# LPC5411x register map
Vendor: nxp.com; File version: 1.2
CPU: CM4 r0p1, little endian, MPU, FPU, VTOR, vendor SysTick, 3 interrupt priority bits
Registers are 32-bit, read-write, reset 0x0 unless marked. A register's access mark holds for its fields unless they carry their own. Offsets are from the block's base; [hi:lo] are bit positions; lines under a group give offsets from that group; {n}, {i} and the like mark numbered series.

## MRT — LPC5411x Multi-Rate Timer (MRT)
Base 0x4000D000
{0x0+0x10*i} MyAddressBlock1_RF[{i}] (i=0..3) group
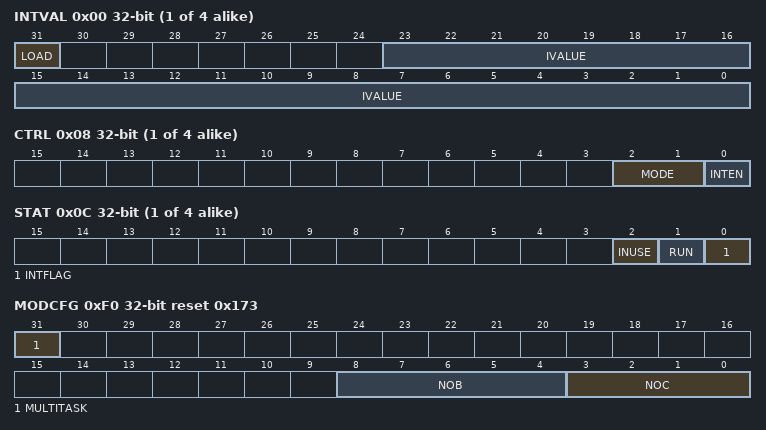
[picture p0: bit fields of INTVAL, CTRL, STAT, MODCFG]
  0x00 INTVAL — MRT Time interval value register. This value is loaded into the TIMER register.
    [31] LOAD — Determines how the timer interval value IVALUE -1 is loaded into the TIMERn register. This bit is write-only. Reading this bit always returns 0.
      0=NO_FORCE_LOAD (No force load. The load from the INTVALn register to the TIMERn register is processed at the end of the time interval if the repeat mode is selected.); 1=FORCE_LOAD (Force load. The INTVALn interval value IVALUE -1 is immediately loaded into the TIMERn register while TIMERn is running.)
    [23:0] IVALUE — Time interval load value. This value is loaded into the TIMERn register and the MRT channel n starts counting down from IVALUE -1. If the timer is idle, writing a non-zero value to this bit field starts the timer immediately. If the timer is running, writing a zero to this bit field does the following: If LOAD = 1, the timer stops immediately. If LOAD = 0, the timer stops at the end of the time interval.
  0x04 TIMER reset 0xFFFFFF — MRT Timer register. This register reads the value of the down-counter.
    [23:0] VALUE ro — Holds the current timer value of the down-counter. The initial value of the TIMERn register is loaded as IVALUE - 1 from the INTVALn register either at the end of the time interval or immediately in the following cases: INTVALn register is updated in the idle state. INTVALn register is updated with LOAD = 1. When the timer is in idle state, reading this bit fields returns -1 (0x00FF FFFF).
  0x08 CTRL — MRT Control register. This register controls the MRT modes.
    [2:1] MODE — Selects timer mode.
      0=REPEAT_INTERRUPT_MODE; 1=ONE_SHOT_INTERRUPT_MODE; 2=ONE_SHOT_STALL_MODE
    [0] INTEN — Enable the TIMERn interrupt.
      0=DISABLED (Disabled. TIMERn interrupt is disabled.); 1=ENABLED (Enabled. TIMERn interrupt is enabled.)
  0x0C STAT — MRT Status register.
    [2] INUSE — Channel In Use flag. Operating details depend on the MULTITASK bit in the MODCFG register, and affects the use of IDLE_CH. See Idle channel register for details of the two operating modes.
      0=NO (This channel is not in use.); 1=YES (This channel is in use.)
    [1] RUN — Indicates the state of TIMERn. This bit is read-only.
      0=IDLE_STATE (Idle state. TIMERn is stopped.); 1=RUNNING (Running. TIMERn is running.)
    [0] INTFLAG — Monitors the interrupt flag.
      0=NO_PENDING_INTERRUPT (No pending interrupt. Writing a zero is equivalent to no operation.); 1=PENDING_INTERRUPT (Pending interrupt. The interrupt is pending because TIMERn has reached the end of the time interval. If the INTEN bit in the CONTROLn is also set to 1, the interrupt for timer channel n and the global interrupt are raised. Writing a 1 to this bit clears the interrupt request.)
0xF0 MODCFG reset 0x173 — Module Configuration register. This register provides information about this particular MRT instance, and allows choosing an overall mode for the idle channel feature.
  [31] MULTITASK — Selects the operating mode for the INUSE flags and the IDLE_CH register.
    0=HARDWARE_STATUS_MODE (Hardware status mode. In this mode, the INUSE(n) flags for all channels are reset.); 1=MULTI_TASK_MODE
  [8:4] NOB — Identifies the number of timer bits in this MRT. (24 bits wide on this device.)
  [3:0] NOC — Identifies the number of channels in this MRT.(4 channels on this device.)
0xF4 IDLE_CH — Idle channel register. This register returns the number of the first idle channel.
  [7:4] CHAN ro — Idle channel. Reading the CHAN bits, returns the lowest idle timer channel. The number is positioned such that it can be used as an offset from the MRT base address in order to access the registers for the allocated channel. If all timer channels are running, CHAN = 0xF. See text above for more details.
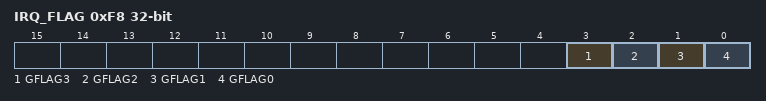
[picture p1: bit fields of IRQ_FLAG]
0xF8 IRQ_FLAG — Global interrupt flag register
  [3] GFLAG3 — Monitors the interrupt flag of TIMER3. See description of channel 0.
  [2] GFLAG2 — Monitors the interrupt flag of TIMER2. See description of channel 0.
  [1] GFLAG1 — Monitors the interrupt flag of TIMER1. See description of channel 0.
  [0] GFLAG0 — Monitors the interrupt flag of TIMER0.
    0=NO_PENDING_INTERRUPT (No pending interrupt. Writing a zero is equivalent to no operation.); 1=PENDING_INTERRUPT (Pending interrupt. The interrupt is pending because TIMER0 has reached the end of the time interval. If the INTEN bit in the CONTROL0 register is also set to 1, the interrupt for timer channel 0 and the global interrupt are raised. Writing a 1 to this bit clears the interrupt request.)
